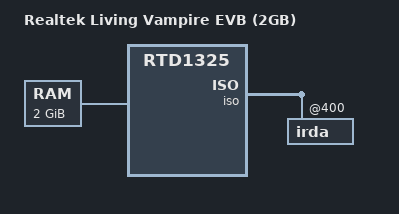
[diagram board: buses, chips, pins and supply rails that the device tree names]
// SPDX-License-Identifier: (GPL-2.0-or-later OR BSD-2-Clause)
/*
 * Copyright (c) 2023 Realtek Semiconductor Corp.
 */

/dts-v1/;

#include "rtd1325-livingvampire.dtsi"

/ {
	compatible = "realtek,livingvampire", "realtek,rtd1325";
	model = "Realtek Living Vampire EVB (2GB)";

	memory@40000 {
		device_type = "memory";
		reg = <0x00040000 0x7ffc0000>; /* 2 GB */
	};
};

&iso {
	irda: irda@400 {
		hw,rc-map-name = "rc-realtek-sri";
	};
};

&irda {
	wakeup-key = <116>,<148>,<149>,<377>,<531>,<532>;
};

&tee {
	reg = <0x10100000 0x04100000>;
};
